# KM1M7CF14 register map
Vendor: Nuvoton Technology Corporation Japan; Series: KM1M7CF; File version: 1.0.3
CPU: CM7 r1p2, little endian, MPU, FPU, double-precision FPU, I-cache, D-cache, ITCM, DTCM, 4 interrupt priority bits
Registers are 32-bit, read-write, no defined reset value unless marked. A register's access mark holds for its fields unless they carry their own. Offsets are from the block's base; [hi:lo] are bit positions; {n}, {i} and the like mark numbered series.

## PPWM — Power Control PWM
Base 0x40020000
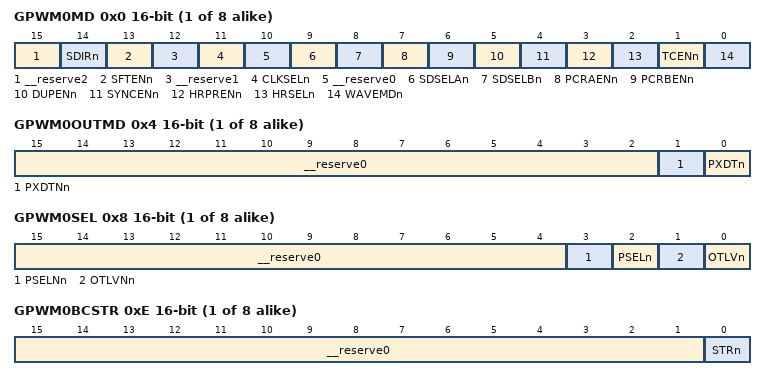
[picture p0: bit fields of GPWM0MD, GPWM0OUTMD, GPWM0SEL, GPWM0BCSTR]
{0x0+0x100*i} GPWM{i}MD 16-bit access per field (i=0..7) — GPWM{i} Mode Register
  [15] __reserve2 ro — "0" is always read out.
  [14] SDIRn rw — Shift direction control
  [13] SFTENn rw — PWM output shift function enable
  [12] __reserve1 ro — "0" is always read out.
  [11] CLKSELn rw — Count clock selection
  [10] __reserve0 rw — This bit must be set to "0".
  [9] SDSELAn rw — GPWMnOUTMD buffer mode
  [8] SDSELBn rw — GPWMnSEL buffer mode
  [7] PCRAENn rw — Double buffer load timing enable (GPWMnBC underflow)
  [6] PCRBENn rw — Double buffer load timing enable (GPWMnBC overflow)
  [5] DUPENn rw — Double buffer updating enable register selection
  [4] SYNCENn rw — Synchronous start function (MFA) enable
  [3] HRPRENn rw — High resolution cycle function enable
  [2] HRSELn rw — High resolution output function enable
  [1] TCENn rw — PWM Operation control
  [0] WAVEMDn rw — PWM waveform mode selection
{0x4+0x100*i} GPWM{i}OUTMD 16-bit access per field (i=0..7) — GPWM{i} Output Polarity Control Register
  [15:2] __reserve0 ro — "0" is always read out.
  [1] PXDTNn rw — NGPWMn output polarity
  [0] PXDTn rw — GPWMn output polarity
{0x8+0x100*i} GPWM{i}SEL 16-bit access per field (i=0..7) — GPWM{i} Output Control Register
  [15:4] __reserve0 ro — "0" is always read out.
  [3] PSELNn rw — NGPWMn output sources
  [2] PSELn rw — GPWMn output sources
  [1] OTLVNn rw — NGPWMn High/Low-level output
  [0] OTLVn rw — GPWMn High/Low-level output
{0xC+0x100*i} GPWM{i}BC 16-bit ro (i=0..7) — GPWM{i}BC Value Read Register
  [15:0] BCn — Read the binary counter value of GPWMn
{0xE+0x100*i} GPWM{i}BCSTR 16-bit ro (i=0..7) — GPWM{i}BC Status Read Register
  [15:1] __reserve0 — "0" is always read out.
  [0] STRn — Counting status read of GPWMn binary counter
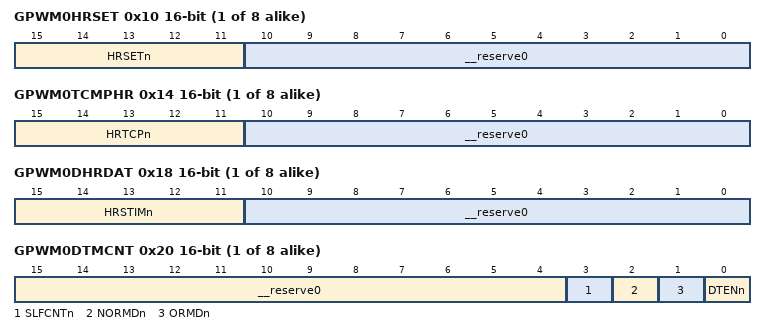
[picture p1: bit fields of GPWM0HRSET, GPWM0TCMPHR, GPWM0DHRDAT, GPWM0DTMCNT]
{0x10+0x100*i} GPWM{i}HRSET 16-bit access per field (i=0..7) — GPWM{i} High Resolution Cycle Setting Register
  [15:11] HRSETn rw — Set high resolution cycle
  [10:0] __reserve0 ro — "0" is always read out.
{0x12+0x100*i} GPWM{i}SET 16-bit (i=0..7) — GPWM{i} Cycle Setting Register
  [15:0] SETn — Set the cycle to the GPWMn 16-bit counter.
{0x14+0x100*i} GPWM{i}TCMPHR 16-bit access per field (i=0..7) — GPWM{i} High Resolution Phase Comparison Setting Register
  [15:11] HRTCPn rw — Set phase comparison high resolution
  [10:0] __reserve0 ro — "0" is always read out.
{0x16+0x100*i} GPWM{i}TCMP 16-bit (i=0..7) — GPWM{i} Phase Comparison Setting Register
  [15:0] TCPn — Set the timing to change output of GPWMn.
{0x18+0x100*i} GPWM{i}DHRDAT 16-bit access per field (i=0..7) — GPWM{i} High Resolution Output Shift Amount Setting Register
  [15:11] HRSTIMn rw — Set high resolution output shift amount
  [10:0] __reserve0 ro — "0" is always read out.
{0x1A+0x100*i} GPWM{i}DDAT 16-bit (i=0..7) — GPWM{i} Output Shift Amount Setting Register
  [15:0] STIMn — Set GPWMn output shift amount
{0x20+0x100*i} GPWM{i}DTMCNT 16-bit access per field (i=0..7) — GPWM{i} Dead Time Control Register
  [15:4] __reserve0 ro — "0" is always read out.
  [3] SLFCNTn rw — Dead time width automatic control enable
  [2] NORMDn rw — NGPWMn dead time insertion logic
  [1] ORMDn rw — GPWMn dead time insertion logic
  [0] DTENn rw — Dead time insertion
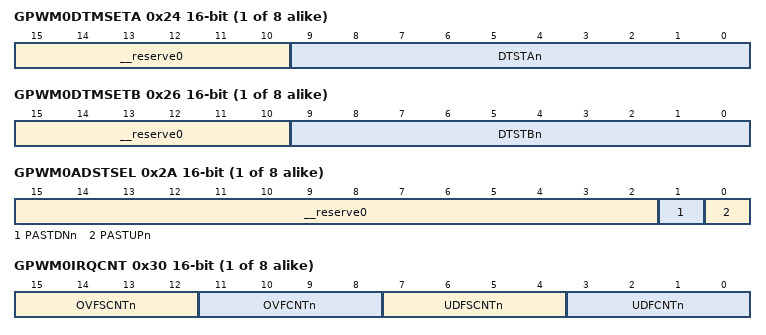
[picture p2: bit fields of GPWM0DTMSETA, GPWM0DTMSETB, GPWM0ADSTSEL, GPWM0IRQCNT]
{0x24+0x100*i} GPWM{i}DTMSETA 16-bit access per field (i=0..7) — GPWM{i} Dead Time Setting Register A
  [15:10] __reserve0 ro — "0" is always read out.
  [9:0] DTSTAn rw — Set dead time for GPWMn.
{0x26+0x100*i} GPWM{i}DTMSETB 16-bit access per field (i=0..7) — GPWM{i} Dead Time Setting Register B
  [15:10] __reserve0 ro — "0" is always read out.
  [9:0] DTSTBn rw — Set dead time for NGPWMn.
{0x28+0x100*i} GPWM{i}ADST 16-bit (i=0..7) — GPWM{i} Synchronous Trigger Setting Register
  [15:0] PASTn — Set the value of starting GPWMn synchronous A/D.
{0x2A+0x100*i} GPWM{i}ADSTSEL 16-bit access per field (i=0..7) — GPWM{i} Synchronous Trigger Polarity Selection Register
  [15:2] __reserve0 ro — "0" is always read out.
  [1] PASTDNn rw — Set the timing of synchronous trigger generation.
  [0] PASTUPn rw — Set the timing of synchronous trigger generation.
{0x2C+0x100*i} GPWM{i}ADBC 16-bit ro (i=0..7) — GPWM{i} Synchronous Binary Counter Read Register
  [15:0] ADBCn — Read the binary count for starting GPWMn synchronous A/D.
{0x30+0x100*i} GPWM{i}IRQCNT 16-bit (i=0..7) — GPWM{i} UDF/OVF Interrupt Output Control Register
  [15:12] OVFSCNTn — The number of times GPWMn overflow is reduced (First time)
  [11:8] OVFCNTn — The number of times GPWMn overflow is reduced (Second time or later)
  [7:4] UDFSCNTn — The number of times GPWMn underflow is reduced (First time)
  [3:0] UDFCNTn — The number of times GPWMn underflow is reduced (Second time or later)
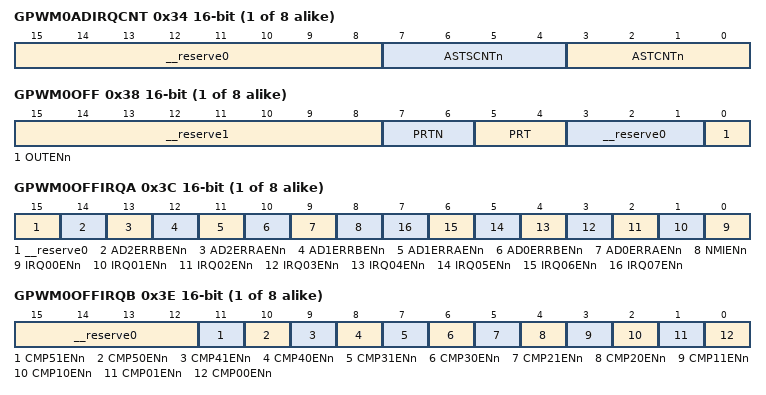
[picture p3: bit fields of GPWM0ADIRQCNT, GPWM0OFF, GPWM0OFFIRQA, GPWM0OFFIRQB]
{0x34+0x100*i} GPWM{i}ADIRQCNT 16-bit access per field (i=0..7) — GPWM{i} A/D Start Interrupt Output Control Register
  [15:8] __reserve0 ro — "0" is always read out.
  [7:4] ASTSCNTn rw — The number of times GPWMn synchronous A/D start is reduced (First time)
  [3:0] ASTCNTn rw — The number of times GPWMn synchronous A/D start is reduced (Second time or lateｒ)
{0x38+0x100*i} GPWM{i}OFF 16-bit access per field (i=0..7) — GPWM{i} Pin Protection Control Register
  [15:8] __reserve1 ro — "0" is always read out.
  [7:6] PRTN rw — NGPWMOUTn output pin protection function
  [5:4] PRT rw — GPWMOUTn output pin protection function
  [3:1] __reserve0 ro — "0" is always read out.
  [0] OUTENn rw — GPWMn pin output enable
{0x3C+0x100*i} GPWM{i}OFFIRQA 16-bit access per field (i=0..7) — GPWM{i} Pin Protection Factor Selection Register A
  [15] __reserve0 ro — "0" is always read out.
  [14] AD2ERRBENn rw — Protection factor control by A/D2 Conversion Error Detection B
  [13] AD2ERRAENn rw — Protection factor control by A/D2 Conversion Error Detection
  [12] AD1ERRBENn rw — Protection factor control by A/D1 Conversion Error Detection B
  [11] AD1ERRAENn rw — Protection factor control by A/D1 Conversion Error Detection
  [10] AD0ERRBENn rw — Protection factor control by A/D0 Conversion Error Detection B
  [9] AD0ERRAENn rw — Protection factor control by A/D0 Conversion Error Detection
  [8] NMIENn rw — Protection factor control by NMI
  [n] IRQ{n:02}ENn rw (n=0..7) — Protection factor control by External Interrupt {n}
{0x3E+0x100*i} GPWM{i}OFFIRQB 16-bit access per field (i=0..7) — GPWM{i} Pin Protection Factor Selection Register B
  [15:12] __reserve0 ro — "0" is always read out.
  [11] CMP51ENn rw — Protection factor control by Comparator 51 Detection
  [10] CMP50ENn rw — Protection factor control by Comparator 50 Detection
  [9] CMP41ENn rw — Protection factor control by Comparator 41 Detection
  [8] CMP40ENn rw — Protection factor control by Comparator 40 Detection
  [7] CMP31ENn rw — Protection factor control by Comparator 31 Detection
  [6] CMP30ENn rw — Protection factor control by Comparator 30 Detection
  [5] CMP21ENn rw — Protection factor control by Comparator 21 Detection
  [4] CMP20ENn rw — Protection factor control by Comparator 20 Detection
  [3] CMP11ENn rw — Protection factor control by Comparator 11 Detection
  [2] CMP10ENn rw — Protection factor control by Comparator 10 Detection
  [1] CMP01ENn rw — Protection factor control by Comparator 01 Detection
  [0] CMP00ENn rw — Protection factor control by Comparator 00 Detection
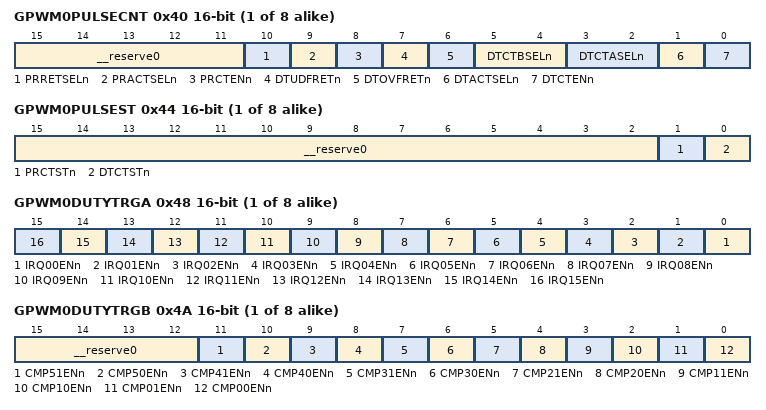
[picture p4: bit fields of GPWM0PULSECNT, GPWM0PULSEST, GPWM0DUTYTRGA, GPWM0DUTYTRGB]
{0x40+0x100*i} GPWM{i}PULSECNT 16-bit access per field (i=0..7) — GPWM{i} Pulse Control Register
  [15:11] __reserve0 ro — "0" is always read out.
  [10] PRRETSELn rw — Period cut operation selection
  [9] PRACTSELn rw — Period cut start factor polarity selection
  [8] PRCTENn rw — Period Cut enable
  [7] DTUDFRETn rw — Control of the return of duty cut by the underflow
  [6] DTOVFRETn rw — Control of the return of duty cut by the overflow
  [5:4] DTCTBSELn rw — NGPWMn operation selection when the duty cut
  [3:2] DTCTASELn rw — GPWMn operation selection when the duty cut
  [1] DTACTSELn rw — Duty cut start factor polarity selection
  [0] DTCTENn rw — Duty Cut enable
{0x44+0x100*i} GPWM{i}PULSEST 16-bit access per field (i=0..7) — GPWM{i} Pulse Control Status Register
  [15:2] __reserve0 ro — "0" is always read out.
  [1] PRCTSTn rw — Period cut state
  [0] DTCTSTn rw — Duty cut state
{0x48+0x100*i} GPWM{i}DUTYTRGA 16-bit (i=0..7) — GPWM{i} Duty Cut Factor Selection Register A
  [n] IRQ{n:02}ENn (n=0..15) — Duty cut start factor selection by External Interrupt {n}
{0x4A+0x100*i} GPWM{i}DUTYTRGB 16-bit access per field (i=0..7) — GPWM{i} Duty Cut Factor Selection Register B
  [15:12] __reserve0 ro — "0" is always read out.
  [11] CMP51ENn rw — Duty cut start factor selection by Comparator 51 Detection
  [10] CMP50ENn rw — Duty cut start factor selection by Comparator 50 Detection
  [9] CMP41ENn rw — Duty cut start factor selection by Comparator 41 Detection
  [8] CMP40ENn rw — Duty cut start factor selection by Comparator 40 Detection
  [7] CMP31ENn rw — Duty cut start factor selection by Comparator 31 Detection
  [6] CMP30ENn rw — Duty cut start factor selection by Comparator 30 Detection
  [5] CMP21ENn rw — Duty cut start factor selection by Comparator 21 Detection
  [4] CMP20ENn rw — Duty cut start factor selection by Comparator 20 Detection
  [3] CMP11ENn rw — Duty cut start factor selection by Comparator 11 Detection
  [2] CMP10ENn rw — Duty cut start factor selection by Comparator 10 Detection
  [1] CMP01ENn rw — Duty cut start factor selection by Comparator 01 Detection
  [0] CMP00ENn rw — Duty cut start factor selection by Comparator 00 Detection
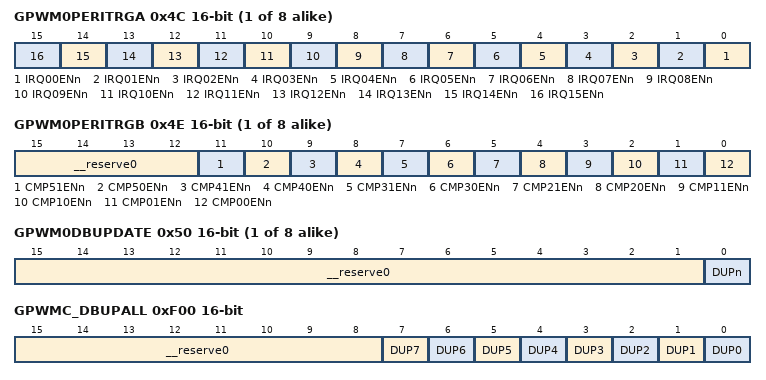
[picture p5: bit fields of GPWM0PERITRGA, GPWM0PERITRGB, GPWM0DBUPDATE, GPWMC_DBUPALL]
{0x4C+0x100*i} GPWM{i}PERITRGA 16-bit (i=0..7) — GPWM{i} Period Cut Factor Selection Register A
  [n] IRQ{n:02}ENn (n=0..15) — Period cut start factor selection by External Interrupt {n}
{0x4E+0x100*i} GPWM{i}PERITRGB 16-bit access per field (i=0..7) — GPWM{i} Period Cut Factor Selection Register B
  [15:12] __reserve0 ro — "0" is always read out.
  [11] CMP51ENn rw — Period cut start factor selection by Comparator 51 Detection
  [10] CMP50ENn rw — Period cut start factor selection by Comparator 50 Detection
  [9] CMP41ENn rw — Period cut start factor selection by Comparator 41 Detection
  [8] CMP40ENn rw — Period cut start factor selection by Comparator 40 Detection
  [7] CMP31ENn rw — Period cut start factor selection by Comparator 31 Detection
  [6] CMP30ENn rw — Period cut start factor selection by Comparator 30 Detection
  [5] CMP21ENn rw — Period cut start factor selection by Comparator 21 Detection
  [4] CMP20ENn rw — Period cut start factor selection by Comparator 20 Detection
  [3] CMP11ENn rw — Period cut start factor selection by Comparator 11 Detection
  [2] CMP10ENn rw — Period cut start factor selection by Comparator 10 Detection
  [1] CMP01ENn rw — Period cut start factor selection by Comparator 01 Detection
  [0] CMP00ENn rw — Period cut start factor selection by Comparator 00 Detection
{0x50+0x100*i} GPWM{i}DBUPDATE 16-bit access per field (i=0..7) — GPWM{i} Double Buffer Updating Enable Register
  [15:1] __reserve0 ro — "0" is always read out.
  [0] DUPn rw — Double buffer updating enable
0xF00 GPWMC_DBUPALL 16-bit access per field — GPWM Double Buffer Collective Updating Enable Register
  [15:8] __reserve0 ro — "0" is always read out.
  [n] DUP{n} rw (n=0..7) — GPWM{n} double buffer updating enable
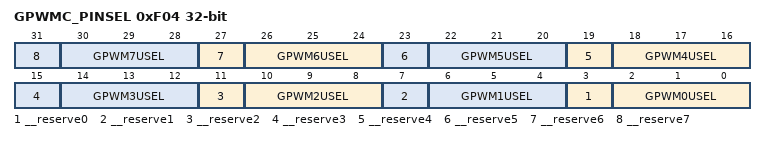
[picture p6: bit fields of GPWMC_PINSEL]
0xF04 GPWMC_PINSEL access per field — GPWMU Pin Function Selection Register
  [4n+3] __reserve{n} ro (n=0..7) — "0" is always read out.
  [4n+2:4n] GPWM{n}USEL rw (n=0..7) — GPWM{n}U pin function selection
